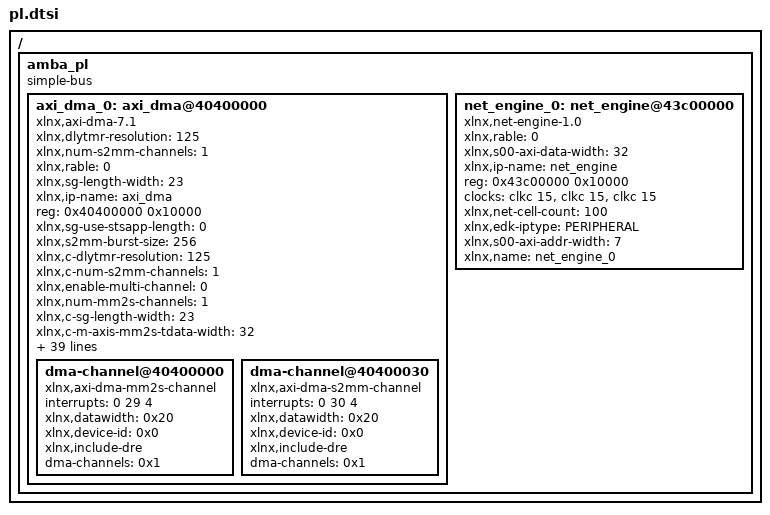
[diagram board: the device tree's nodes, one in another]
/ {
	amba_pl: amba_pl {
		ranges;
		compatible = "simple-bus";
		#address-cells = <1>;
		#size-cells = <1>;
		axi_dma_0: axi_dma@40400000 {
			xlnx,dlytmr-resolution = <125>;
			xlnx,num-s2mm-channels = <1>;
			xlnx,rable = <0>;
			xlnx,sg-length-width = <23>;
			xlnx,ip-name = "axi_dma";
			reg = <0x40400000 0x10000>;
			xlnx,sg-use-stsapp-length = <0>;
			xlnx,s2mm-burst-size = <256>;
			xlnx,c-dlytmr-resolution = <125>;
			xlnx,c-num-s2mm-channels = <1>;
			xlnx,enable-multi-channel = <0>;
			xlnx,num-mm2s-channels = <1>;
			xlnx,c-sg-length-width = <23>;
			interrupt-names = "mm2s_introut" , "s2mm_introut";
			compatible = "xlnx,axi-dma-7.1" , "xlnx,axi-dma-1.00.a";
			xlnx,c-m-axis-mm2s-tdata-width = <32>;
			xlnx,c-sg-use-stsapp-length = <0>;
			xlnx,c-s2mm-burst-size = <256>;
			xlnx,mm2s-burst-size = <256>;
			xlnx,c-enable-multi-channel = <0>;
			xlnx,c-num-mm2s-channels = <1>;
			interrupt-parent = <&intc>;
			xlnx,include-s2mm-dre = <1>;
			xlnx,c-mm2s-burst-size = <256>;
			status = "okay";
			xlnx,c-include-s2mm-dre = <1>;
			xlnx,include-mm2s-dre = <1>;
			xlnx,name = "axi_dma_0";
			interrupts = < 0 29 4 0 30 4 >;
			xlnx,c-include-sg = <0>;
			xlnx,c-m-axi-s2mm-data-width = <32>;
			xlnx,include-s2mm-sf = <1>;
			xlnx,c-include-mm2s-dre = <1>;
			xlnx,include-s2mm = <1>;
			clocks = <&clkc 15>, <&clkc 15>, <&clkc 15>;
			xlnx,addrwidth = <0x20>;
			xlnx,c-m-axi-mm2s-data-width = <32>;
			xlnx,edk-iptype = "PERIPHERAL";
			xlnx,c-include-s2mm-sf = <1>;
			xlnx,include-mm2s-sf = <1>;
			clock-names = "m_axi_mm2s_aclk" , "m_axi_s2mm_aclk" , "s_axi_lite_aclk";
			xlnx,c-include-s2mm = <1>;
			xlnx,c-addr-width = <32>;
			xlnx,c-single-interface = <0>;
			xlnx,include-mm2s = <1>;
			xlnx,c-s-axis-s2mm-tdata-width = <32>;
			xlnx,s2mm-data-width = <0x20>;
			xlnx,c-include-mm2s-sf = <1>;
			xlnx,prmry-is-aclk-async = <0>;
			xlnx,c-include-mm2s = <1>;
			xlnx,increase-throughput = <0>;
			xlnx,micro-dma = <0>;
			xlnx,mm2s-data-width = <0x20>;
			xlnx,c-prmry-is-aclk-async = <0>;
			xlnx,c-sg-include-stscntrl-strm = <0>;
			xlnx,c-increase-throughput = <0>;
			xlnx,c-micro-dma = <0>;
			dma-channel@40400000 {
				interrupts = <0 29 4>;
				xlnx,datawidth = <0x20>;
				xlnx,device-id = <0x0>;
				compatible = "xlnx,axi-dma-mm2s-channel";
				xlnx,include-dre;
				dma-channels = <0x1>;
			};
			dma-channel@40400030 {
				interrupts = <0 30 4>;
				xlnx,datawidth = <0x20>;
				xlnx,device-id = <0x0>;
				compatible = "xlnx,axi-dma-s2mm-channel";
				xlnx,include-dre;
				dma-channels = <0x1>;
			};
		};
		net_engine_0: net_engine@43c00000 {
			compatible = "xlnx,net-engine-1.0";
			xlnx,rable = <0>;
			xlnx,s00-axi-data-width = <32>;
			xlnx,ip-name = "net_engine";
			reg = <0x43c00000 0x10000>;
			clocks = <&clkc 15>, <&clkc 15>, <&clkc 15>;
			xlnx,net-cell-count = <100>;
			xlnx,edk-iptype = "PERIPHERAL";
			status = "okay";
			xlnx,s00-axi-addr-width = <7>;
			clock-names = "m00_axis_aclk" , "s00_axi_aclk" , "s00_axis_aclk";
			xlnx,name = "net_engine_0";
		};
	};
};
